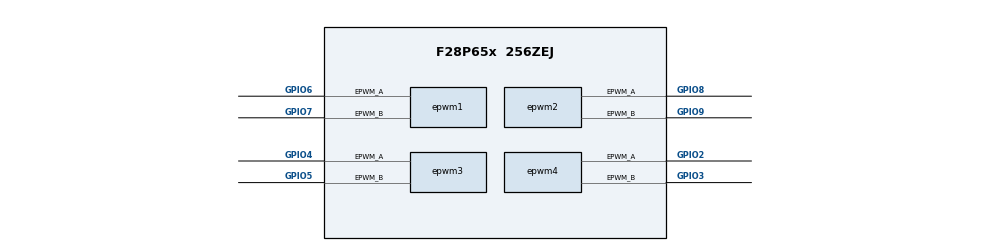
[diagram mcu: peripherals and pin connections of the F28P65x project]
/**
 * @cliArgs --device "F28P65x" --package "256ZEJ" --part "F28P65x_256ZEJ" --context "CPU1" --product "C2000WARE@5.00.00.00"
 * @versions {"tool":"1.17.0+3047"}
 */

/**
 * Import the modules used in this configuration.
 */
const epwm     = scripting.addModule("/driverlib/epwm.js", {}, false);
const epwm1    = epwm.addInstance();
const epwm2    = epwm.addInstance();
const epwm3    = epwm.addInstance();
const epwm4    = epwm.addInstance();
const iclxbar  = scripting.addModule("/driverlib/iclxbar.js", {}, false);
const iclxbar1 = iclxbar.addInstance();
const iclxbar2 = iclxbar.addInstance();

/**
 * Write custom configuration values to the imported modules.
 */
epwm1.epwmTimebase_period                                      = 1999;
epwm1.epwmTimebase_syncOutPulseMode                            = ["EPWM_SYNC_OUT_PULSE_ON_ALL"];
epwm1.epwmActionQualifier_EPWM_AQ_OUTPUT_A_ON_TIMEBASE_ZERO    = "EPWM_AQ_OUTPUT_HIGH";
epwm1.epwmActionQualifier_EPWM_AQ_OUTPUT_A_ON_TIMEBASE_UP_CMPA = "EPWM_AQ_OUTPUT_LOW";
epwm1.epwmTimebase_counterMode                                 = "EPWM_COUNTER_MODE_UP";
epwm1.epwmActionQualifier_EPWM_AQ_OUTPUT_B_ON_TIMEBASE_ZERO    = "EPWM_AQ_OUTPUT_LOW";
epwm1.epwmActionQualifier_EPWM_AQ_OUTPUT_B_ON_TIMEBASE_UP_CMPB = "EPWM_AQ_OUTPUT_HIGH";
epwm1.epwmMinDeadBand_EnableA                                  = true;
epwm1.epwmMinDeadBand_EnableB                                  = true;
epwm1.epwmMinDeadBand_B_configBlockSignal                      = "EPWM_MINDB_BLOCKING_SIGNAL_SWAPBLOCK";
epwm1.epwmMinDeadBand_A_configBlockSignal                      = "EPWM_MINDB_BLOCKING_SIGNAL_SWAPBLOCK";
epwm1.epwmMinDeadBand_A_setDelay                               = 200;
epwm1.epwmMinDeadBand_B_setDelay                               = 200;
epwm1.epwmCounterCompare_cmpA                                  = 1100;
epwm1.epwmCounterCompare_cmpB                                  = 900;
epwm1.$name                                                    = "myEPWM4";
epwm1.epwm.$assign                                             = "EPWM4";
epwm1.epwm.epwm_aPin.$assign                                   = "GPIO6";
epwm1.epwm.epwm_bPin.$assign                                   = "GPIO7";

epwm2.epwmTimebase_counterMode                                 = "EPWM_COUNTER_MODE_UP";
epwm2.epwmTimebase_syncOutPulseMode                            = ["EPWM_SYNC_OUT_PULSE_ON_ALL"];
epwm2.epwmCounterCompare_cmpA                                  = 500;
epwm2.epwmTimebase_period                                      = 999;
epwm2.epwmCounterCompare_cmpB                                  = 500;
epwm2.epwmActionQualifier_EPWM_AQ_OUTPUT_A_ON_TIMEBASE_ZERO    = "EPWM_AQ_OUTPUT_HIGH";
epwm2.epwmActionQualifier_EPWM_AQ_OUTPUT_A_ON_TIMEBASE_UP_CMPA = "EPWM_AQ_OUTPUT_LOW";
epwm2.epwmActionQualifier_EPWM_AQ_OUTPUT_B_ON_TIMEBASE_ZERO    = "EPWM_AQ_OUTPUT_LOW";
epwm2.epwmActionQualifier_EPWM_AQ_OUTPUT_B_ON_TIMEBASE_UP_CMPB = "EPWM_AQ_OUTPUT_HIGH";
epwm2.epwmICL_EnableA                                          = true;
epwm2.epwmICL_B_OUTHIGH                                        = ["EPWM_MINDB_ICL_LUT_DEC5","EPWM_MINDB_ICL_LUT_DEC7"];
epwm2.epwmICL_B_OUTLOW                                         = ["EPWM_MINDB_ICL_LUT_DEC0","EPWM_MINDB_ICL_LUT_DEC1","EPWM_MINDB_ICL_LUT_DEC2","EPWM_MINDB_ICL_LUT_DEC3","EPWM_MINDB_ICL_LUT_DEC4","EPWM_MINDB_ICL_LUT_DEC6"];
epwm2.epwmICL_EnableB                                          = true;
epwm2.epwmICL_B_selXBAR                                        = "EPWM_MINDB_ICL_XBAR_OUT2";
epwm2.epwmICL_A_OUTHIGH                                        = ["EPWM_MINDB_ICL_LUT_DEC5","EPWM_MINDB_ICL_LUT_DEC7"];
epwm2.epwmICL_A_OUTLOW                                         = ["EPWM_MINDB_ICL_LUT_DEC0","EPWM_MINDB_ICL_LUT_DEC1","EPWM_MINDB_ICL_LUT_DEC2","EPWM_MINDB_ICL_LUT_DEC3","EPWM_MINDB_ICL_LUT_DEC4","EPWM_MINDB_ICL_LUT_DEC6"];
epwm2.$name                                                    = "myEPWM5";
epwm2.epwm.$assign                                             = "EPWM5";
epwm2.epwm.epwm_aPin.$assign                                   = "GPIO8";
epwm2.epwm.epwm_bPin.$assign                                   = "GPIO9";

epwm3.epwmTimebase_counterMode                                 = "EPWM_COUNTER_MODE_UP";
epwm3.epwmTimebase_syncOutPulseMode                            = ["EPWM_SYNC_OUT_PULSE_ON_ALL"];
epwm3.epwmCounterCompare_cmpA                                  = 500;
epwm3.epwmTimebase_period                                      = 999;
epwm3.epwmCounterCompare_cmpB                                  = 500;
epwm3.epwmActionQualifier_EPWM_AQ_OUTPUT_A_ON_TIMEBASE_ZERO    = "EPWM_AQ_OUTPUT_HIGH";
epwm3.epwmActionQualifier_EPWM_AQ_OUTPUT_A_ON_TIMEBASE_UP_CMPA = "EPWM_AQ_OUTPUT_LOW";
epwm3.epwmActionQualifier_EPWM_AQ_OUTPUT_B_ON_TIMEBASE_ZERO    = "EPWM_AQ_OUTPUT_LOW";
epwm3.epwmActionQualifier_EPWM_AQ_OUTPUT_B_ON_TIMEBASE_UP_CMPB = "EPWM_AQ_OUTPUT_HIGH";
epwm3.epwmICL_B_OUTHIGH                                        = ["EPWM_MINDB_ICL_LUT_DEC5","EPWM_MINDB_ICL_LUT_DEC7"];
epwm3.epwmICL_B_OUTLOW                                         = ["EPWM_MINDB_ICL_LUT_DEC0","EPWM_MINDB_ICL_LUT_DEC1","EPWM_MINDB_ICL_LUT_DEC2","EPWM_MINDB_ICL_LUT_DEC3","EPWM_MINDB_ICL_LUT_DEC4","EPWM_MINDB_ICL_LUT_DEC6"];
epwm3.epwmICL_A_OUTLOW                                         = ["EPWM_MINDB_ICL_LUT_DEC0","EPWM_MINDB_ICL_LUT_DEC1","EPWM_MINDB_ICL_LUT_DEC2","EPWM_MINDB_ICL_LUT_DEC3","EPWM_MINDB_ICL_LUT_DEC4","EPWM_MINDB_ICL_LUT_DEC6"];
epwm3.epwmICL_A_OUTHIGH                                        = ["EPWM_MINDB_ICL_LUT_DEC5","EPWM_MINDB_ICL_LUT_DEC7"];
epwm3.$name                                                    = "myEPWM5_NO_ICL";
epwm3.epwm.$assign                                             = "EPWM3";
epwm3.epwm.epwm_aPin.$assign                                   = "GPIO4";
epwm3.epwm.epwm_bPin.$assign                                   = "GPIO5";

epwm4.epwmTimebase_period                                      = 1999;
epwm4.epwmTimebase_syncOutPulseMode                            = ["EPWM_SYNC_OUT_PULSE_ON_ALL"];
epwm4.epwmActionQualifier_EPWM_AQ_OUTPUT_A_ON_TIMEBASE_ZERO    = "EPWM_AQ_OUTPUT_HIGH";
epwm4.epwmActionQualifier_EPWM_AQ_OUTPUT_A_ON_TIMEBASE_UP_CMPA = "EPWM_AQ_OUTPUT_LOW";
epwm4.epwmTimebase_counterMode                                 = "EPWM_COUNTER_MODE_UP";
epwm4.epwmActionQualifier_EPWM_AQ_OUTPUT_B_ON_TIMEBASE_ZERO    = "EPWM_AQ_OUTPUT_LOW";
epwm4.epwmActionQualifier_EPWM_AQ_OUTPUT_B_ON_TIMEBASE_UP_CMPB = "EPWM_AQ_OUTPUT_HIGH";
epwm4.epwmCounterCompare_cmpA                                  = 1100;
epwm4.epwmCounterCompare_cmpB                                  = 900;
epwm4.$name                                                    = "myEPWM4_NO_MINDB";
epwm4.epwm.$assign                                             = "EPWM2";
epwm4.epwm.epwm_aPin.$assign                                   = "GPIO2";
epwm4.epwm.epwm_bPin.$assign                                   = "GPIO3";

iclxbar1.$name        = "myICLXBARINPUT0";
epwm2.ICL_XBAR_A      = iclxbar1;
iclxbar1.iclxbarInput = "EPWM4A_MINDB";
iclxbar1.iclxbarLock  = true;

iclxbar2.$name        = "myICLXBARINPUT1";
iclxbar2.iclxbarInput = "EPWM4B_MINDB";
epwm2.ICL_XBAR_B      = iclxbar2;
iclxbar2.iclxbarLock  = true;
